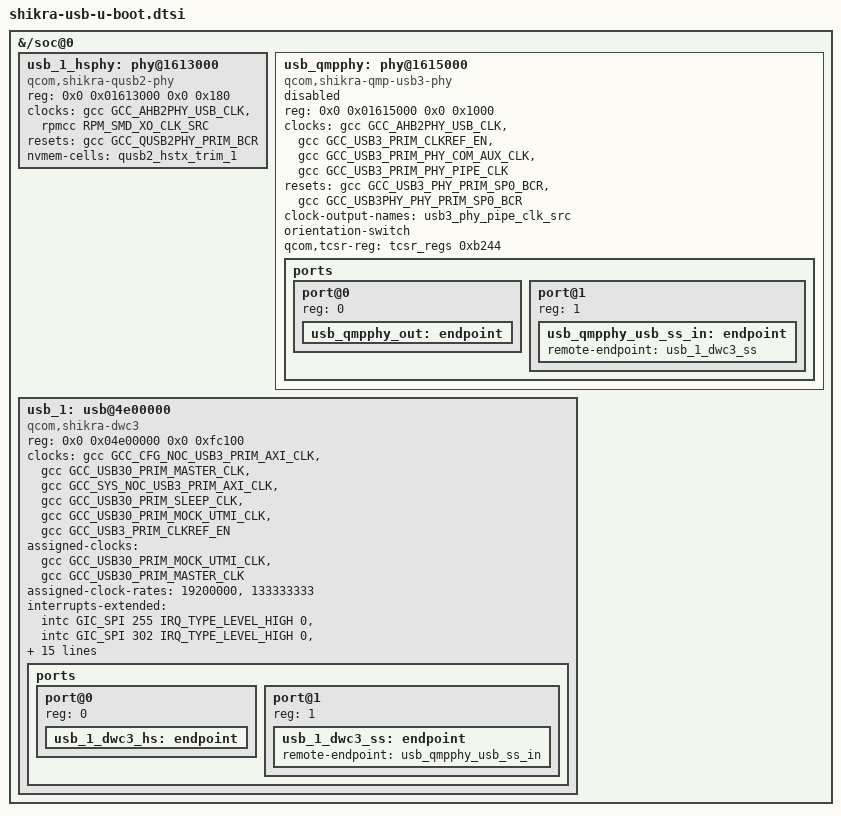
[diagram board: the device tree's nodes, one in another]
// SPDX-License-Identifier: BSD-3-Clause
/*
 * Copyright (c) Qualcomm Technologies, Inc. and/or its subsidiaries.
 *
 * Shikra USB nodes adapted from v3 patch 01/13; peripheral mode from v3 patch
 * 06/13. The imported upstream DTS does not yet provide these nodes.
 */

&{/soc@0} {
	usb_1_hsphy: phy@1613000 {
		compatible = "qcom,shikra-qusb2-phy";
		reg = <0x0 0x01613000 0x0 0x180>;

		clocks = <&gcc GCC_AHB2PHY_USB_CLK>,
			 <&rpmcc RPM_SMD_XO_CLK_SRC>;
		clock-names = "cfg_ahb", "ref";

		resets = <&gcc GCC_QUSB2PHY_PRIM_BCR>;
		nvmem-cells = <&qusb2_hstx_trim_1>;
		#phy-cells = <0>;

		status = "okay";
	};

	usb_qmpphy: phy@1615000 {
		compatible = "qcom,shikra-qmp-usb3-phy";
		reg = <0x0 0x01615000 0x0 0x1000>;

		clocks = <&gcc GCC_AHB2PHY_USB_CLK>,
			 <&gcc GCC_USB3_PRIM_CLKREF_EN>,
			 <&gcc GCC_USB3_PRIM_PHY_COM_AUX_CLK>,
			 <&gcc GCC_USB3_PRIM_PHY_PIPE_CLK>;
		clock-names = "cfg_ahb", "ref", "com_aux", "pipe";

		resets = <&gcc GCC_USB3_PHY_PRIM_SP0_BCR>,
			 <&gcc GCC_USB3PHY_PHY_PRIM_SP0_BCR>;
		reset-names = "phy", "phy_phy";

		#clock-cells = <0>;
		clock-output-names = "usb3_phy_pipe_clk_src";
		#phy-cells = <0>;
		orientation-switch;
		qcom,tcsr-reg = <&tcsr_regs 0xb244>;

		status = "disabled";

		ports {
			#address-cells = <1>;
			#size-cells = <0>;

			port@0 {
				reg = <0>;

				usb_qmpphy_out: endpoint {
				};
			};

			port@1 {
				reg = <1>;

				usb_qmpphy_usb_ss_in: endpoint {
					remote-endpoint = <&usb_1_dwc3_ss>;
				};
			};
		};
	};

	usb_1: usb@4e00000 {
		compatible = "qcom,shikra-dwc3", "qcom,snps-dwc3";
		reg = <0x0 0x04e00000 0x0 0xfc100>;

		clocks = <&gcc GCC_CFG_NOC_USB3_PRIM_AXI_CLK>,
			 <&gcc GCC_USB30_PRIM_MASTER_CLK>,
			 <&gcc GCC_SYS_NOC_USB3_PRIM_AXI_CLK>,
			 <&gcc GCC_USB30_PRIM_SLEEP_CLK>,
			 <&gcc GCC_USB30_PRIM_MOCK_UTMI_CLK>,
			 <&gcc GCC_USB3_PRIM_CLKREF_EN>;
		clock-names = "cfg_noc", "core", "iface", "sleep", "mock_utmi",
			      "xo";

		assigned-clocks = <&gcc GCC_USB30_PRIM_MOCK_UTMI_CLK>,
				  <&gcc GCC_USB30_PRIM_MASTER_CLK>;
		assigned-clock-rates = <19200000>, <133333333>;

		interrupts-extended = <&intc GIC_SPI 255 IRQ_TYPE_LEVEL_HIGH 0>,
				      <&intc GIC_SPI 302 IRQ_TYPE_LEVEL_HIGH 0>,
				      <&intc GIC_SPI 260 IRQ_TYPE_LEVEL_HIGH 0>,
				      <&intc GIC_SPI 422 IRQ_TYPE_LEVEL_HIGH 0>;
		interrupt-names = "dwc_usb3", "pwr_event", "qusb2_phy", "ss_phy_irq";

		iommus = <&apps_smmu 0x120 0x0>;
		phys = <&usb_1_hsphy>, <&usb_qmpphy>;
		phy-names = "usb2-phy", "usb3-phy";
		power-domains = <&gcc GCC_USB30_PRIM_GDSC>;
		resets = <&gcc GCC_USB30_PRIM_BCR>;

		snps,dis_u2_susphy_quirk;
		snps,dis_enblslpm_quirk;
		snps,has-lpm-erratum;
		snps,hird-threshold = /bits/ 8 <0x10>;
		snps,usb3_lpm_capable;
		snps,parkmode-disable-ss-quirk;
		usb-role-switch;
		wakeup-source;

		dr_mode = "peripheral";
		status = "okay";

		ports {
			#address-cells = <1>;
			#size-cells = <0>;

			port@0 {
				reg = <0>;

				usb_1_dwc3_hs: endpoint {
				};
			};

			port@1 {
				reg = <1>;

				usb_1_dwc3_ss: endpoint {
					remote-endpoint = <&usb_qmpphy_usb_ss_in>;
				};
			};
		};
	};
};
